# RE01_1500KB register map
Vendor: Renesas Electronics Corporation; Series: RE01_1500KB; File version: 1.20
CPU: CM0PLUS r0p1, little endian, MPU, no FPU, VTOR, 2 interrupt priority bits
Registers are 8-bit, read-write, reset 0x0 unless marked. A register's access mark holds for its fields unless they carry their own. Offsets are from the block's base; [hi:lo] are bit positions; 'fields as' and 'values as' point back to an identical list.

## AGT0 — Asynchronous General purpose Timer 0
Base 0x40084000
0x00 AGT 16-bit reset 0xFFFF — AGT Counter Register
  [15:0] AGT — 16bit counter and reload registerNOTE : When 1 is written to the TSTOP bit in the AGTCRn register, the 16-bit counter is forcibly stopped and set to FFFFH.
0x02 AGTCMA 16-bit reset 0xFFFF — AGT Compare Match A Register
  [15:0] AGTCMA — AGT Compare Match A RegisterNOTE : When 1 is written to the TSTOP bit in the AGTCRn register, set to FFFFH
0x04 AGTCMB 16-bit reset 0xFFFF — AGT Compare Match B Register
  [15:0] AGTCMB — AGT Compare Match B RegisterNOTE : When 1 is written to the TSTOP bit in the AGTCR register, set to FFFFH
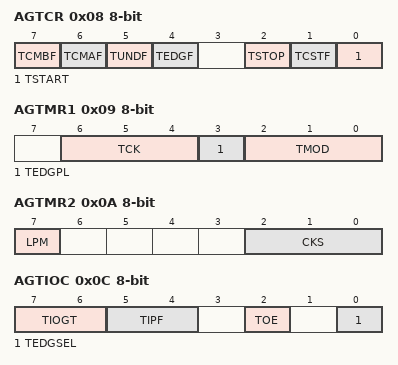
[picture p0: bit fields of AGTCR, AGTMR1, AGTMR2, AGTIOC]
0x08 AGTCR — AGT Control Register
  [7] TCMBF — AGT compare match B flag
    0=No Match; 1=Match
  [6] TCMAF — AGT compare match A flag
    0=No Match; 1=Match
  [5] TUNDF — AGT underflow flag
    0=No underflow; 1=Underflow
  [4] TEDGF — Active edge judgement flag
    0=No active edge received; 1=Active edge received
  [2] TSTOP wo — AGT count forced stop
    0=No effect; 1=The count is forcibly stopped
  [1] TCSTF — AGT count status flag
    0=Count stops; 1=Count starts
  [0] TSTART — AGT count start
    0=Count stops; 1=Count starts
0x09 AGTMR1 — AGT Mode Register 1
  [6:4] TCK — AGT count source select
    0=PCLKB; 1=PCLKB/8; 3=PCLKB/2; 4=Divided clock LOCO specified by bits CKS[2:0] in the AGTMR2 register; 5=Underflow event signal from AGT0; 6=Divided clock fSUB specified by bits CKS[2:0] in the AGTMR2 register; other=others (Setting prohibited)
  [3] TEDGPL — AGTIO edge polarity select
    0=Single-edge; 1=Both-edge
  [2:0] TMOD — AGT operating mode select
    0=Timer mode; 1=Pulse output mode; 2=Event counter mode; 3=Pulse width measurement mode; 4=Pulse period measurement mode; other=others (Setting prohibited)
0x0A AGTMR2 — AGT Mode Register 2
  [7] LPM — Low Power Mode
    0=Normal mode; 1=Low Power mode
  [2:0] CKS — AGTLCLK/LAGTSCLK count source clock frequency division ratio select
    0=1/1; 1=1/2; 2=1/4; 3=1/8; 4=1/16; 5=1/32; 6=1/64; 7=1/128
0x0C AGTIOC — AGT I/O Control Register
  [7:6] TIOGT — AGTIO count control
    0=Event is always counted; 1=Event is counted during polarity period specified for AGTEE; other=others (Setting prohibited)
  [5:4] TIPF — AGTIO input filter select
    0=No filter; 1=Filter sampled at PCLKB; 2=Filter sampled at PCLKB/8; 3=Filter sampled at PCLKB/32
  [2] TOE — AGTO output enable
    0=AGTO output disabled (port); 1=AGTO output enabled
  [0] TEDGSEL — I/O polarity switchFunction varies depending on the operating mode.
0x0D AGTISR — AGT Event Pin Select Register
  [2] EEPS — AGTEEn polarty selection
    0=An event is counted during the low-level period; 1=An event is counted during the high-level period
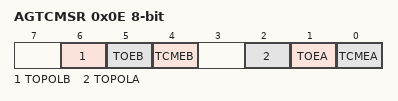
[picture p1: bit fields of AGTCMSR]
0x0E AGTCMSR — AGT Compare Match Function Select Register
  [6] TOPOLB — AGTOBn polarity select
    0=AGTOBn Output is started at low; 1=AGTOBn Output is started at high
  [5] TOEB — AGTOBn output enable
    0=AGTOBn output disabled (port); 1=AGTOBn output enabled
  [4] TCMEB — Compare match B register enable
    0=Disable compare match B register; 1=Enable compare match B register
  [2] TOPOLA — AGTOAn polarity select
    0=AGTOAn Output is started at low; 1=AGTOAn Output is started at high
  [1] TOEA — AGTOAn output enable
    0=AGTOAn output disabled; 1=AGTOAn output enabled
  [0] TCMEA — Compare match A register enable
    0=Disable compare match A register; 1=Enable compare match A register
0x0F AGTIOSEL — AGT Pin Select Register
  [4] TIES — AGTIOn input enable
    0=External event input disable during software standby mode; 1=External event input enable during software standby mode

## AGT1 — Asynchronous General purpose Timer 1
Base 0x40084100
Registers as AGT0; these are added or differ:
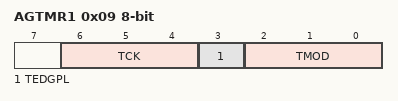
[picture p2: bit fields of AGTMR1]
0x09 AGTMR1 — AGT Mode Register 1
  fields as AGT0.AGTMR1

## Notices in the file
Copyright (C) 2018 - 2020 Renesas Electronics Corporation. All rights reserved.
